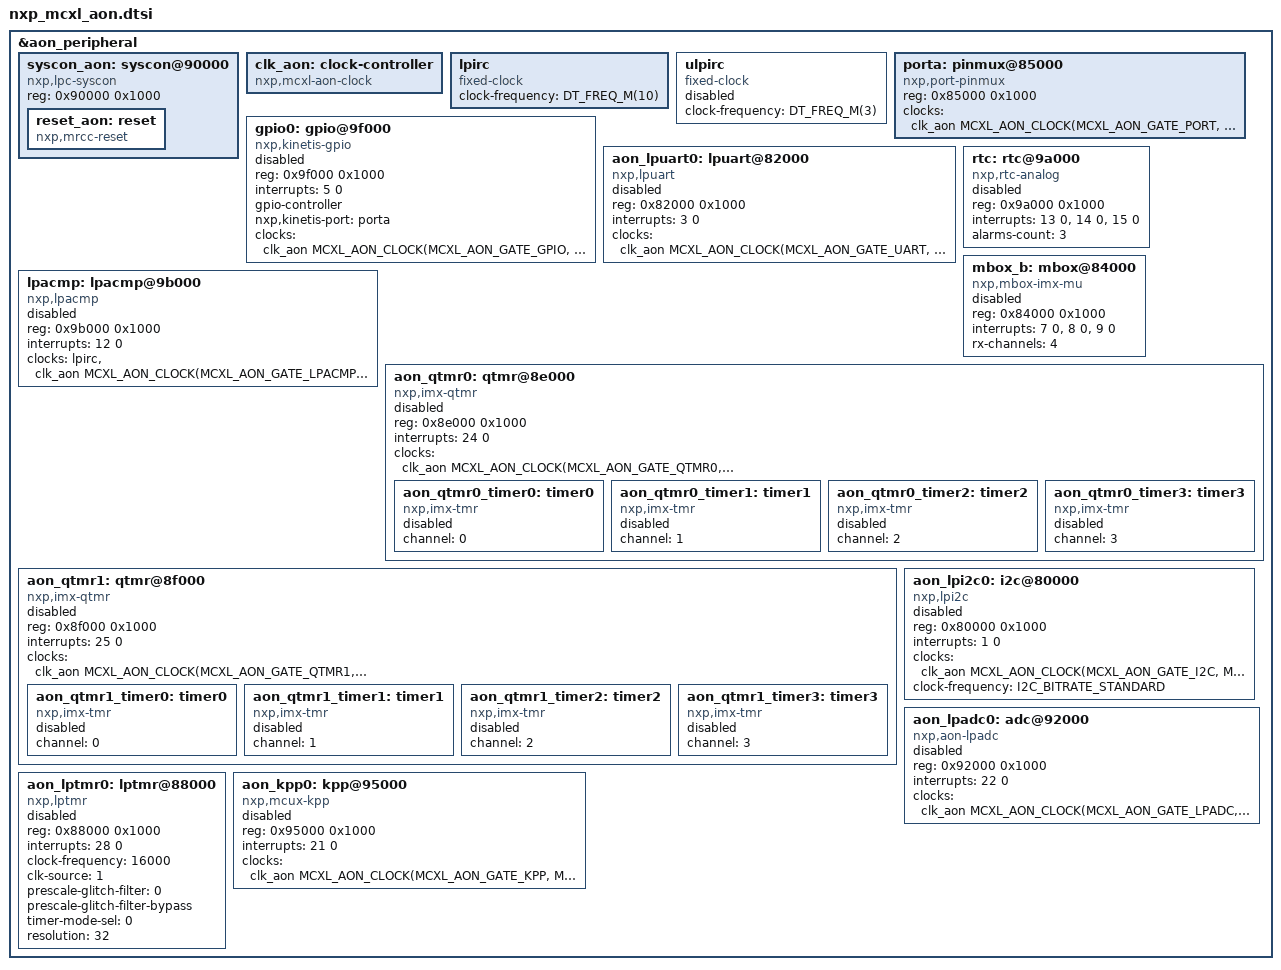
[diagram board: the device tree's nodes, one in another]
/*
 * Copyright 2026 NXP
 *
 * SPDX-License-Identifier: Apache-2.0
 */

#include <freq.h>
#include <zephyr/dt-bindings/clock/nxp_mcxl_aon_clock.h>
#include <zephyr/dt-bindings/i2c/i2c.h>
#include <zephyr/dt-bindings/reset/nxp_syscon_reset_common.h>

&aon_peripheral {
	#address-cells = <1>;
	#size-cells = <1>;

	syscon_aon: syscon@90000 {
		compatible = "nxp,lpc-syscon";
		reg = <0x90000 0x1000>;
		#clock-cells = <1>;

		reset_aon: reset {
			compatible = "nxp,mrcc-reset";
			#reset-cells = <1>;
		};
	};

	clk_aon: clock-controller {
		compatible = "nxp,mcxl-aon-clock";
		#clock-cells = <1>;
	};

	lpirc: lpirc {
		compatible = "fixed-clock";
		#clock-cells = <0>;
		clock-frequency = <DT_FREQ_M(10)>;
	};

	ulpirc: ulpirc {
		compatible = "fixed-clock";
		#clock-cells = <0>;
		clock-frequency = <DT_FREQ_M(3)>;
		status = "disabled";
	};

	porta: pinmux@85000 {
		compatible = "nxp,port-pinmux";
		reg = <0x85000 0x1000>;
		clocks = <&clk_aon MCXL_AON_CLOCK(MCXL_AON_GATE_PORT,
						  MCXL_AON_SEL_NONE, MCXL_AON_CLK_ROOT_SRC_NONE,
						  MCXL_AON_DIV_NONE, MCXL_CLOCK_DIV_BY_1,
						  MCXL_AON_CLK_FLAG_NONE)>;
	};

	gpio0: gpio@9f000 {
		compatible = "nxp,kinetis-gpio";
		status = "disabled";
		reg = <0x9f000 0x1000>;
		interrupts = <5 0>;
		gpio-controller;
		#gpio-cells = <2>;
		nxp,kinetis-port = <&porta>;
		clocks = <&clk_aon MCXL_AON_CLOCK(MCXL_AON_GATE_GPIO,
						  MCXL_AON_SEL_NONE, MCXL_AON_CLK_ROOT_SRC_NONE,
						  MCXL_AON_DIV_NONE, MCXL_CLOCK_DIV_BY_1,
						  MCXL_AON_CLK_FLAG_NONE)>;
	};

	aon_lpuart0: lpuart@82000 {
		compatible = "nxp,lpuart";
		status = "disabled";
		reg = <0x82000 0x1000>;
		interrupts = <3 0>;
		clocks = <&clk_aon MCXL_AON_CLOCK(MCXL_AON_GATE_UART,
						  MCXL_AON_SEL_NONE, MCXL_AON_CLK_ROOT_SRC_NONE,
						  MCXL_AON_DIV_NONE, MCXL_CLOCK_DIV_BY_1,
						  MCXL_AON_CLK_FLAG_NONE)>;
	};

	lpacmp: lpacmp@9b000 {
		compatible = "nxp,lpacmp";
		reg = <0x9b000 0x1000>;
		interrupts = <12 0>;
		clocks = <&lpirc>,
			 <&clk_aon MCXL_AON_CLOCK(MCXL_AON_GATE_LPACMP,
						  MCXL_AON_SEL_NONE, MCXL_AON_CLK_ROOT_SRC_NONE,
						  MCXL_AON_DIV_NONE, MCXL_CLOCK_DIV_BY_1,
						  MCXL_AON_CLK_FLAG_NONE)>;
		clock-names = "aon-clk", "gate";
		status = "disabled";
	};

	rtc: rtc@9a000 {
		compatible = "nxp,rtc-analog";
		reg = <0x9a000 0x1000>;
		interrupts = <13 0>, <14 0>, <15 0>;
		interrupt-names = "alarm0", "alarm1", "alarm2";
		alarms-count = <3>;
		status = "disabled";
	};

	mbox_b: mbox@84000 {
		compatible = "nxp,mbox-imx-mu";
		reg = <0x84000 0x1000>;
		interrupts = <7 0>, <8 0>, <9 0>;
		rx-channels = <4>;
		#mbox-cells = <1>;
		status = "disabled";
	};

	aon_qtmr0: qtmr@8e000 {
		compatible = "nxp,imx-qtmr";
		reg = <0x8e000 0x1000>;
		interrupts = <24 0>;
		clocks = <&clk_aon MCXL_AON_CLOCK(MCXL_AON_GATE_QTMR0,
						  MCXL_AON_SEL_NONE, MCXL_AON_CLK_ROOT_SRC_NONE,
						  MCXL_AON_DIV_NONE, MCXL_CLOCK_DIV_BY_1,
						  MCXL_AON_CLK_FLAG_NONE)>;
		status = "disabled";

		aon_qtmr0_timer0: timer0 {
			compatible = "nxp,imx-tmr";
			channel = <0>;
			status = "disabled";
		};

		aon_qtmr0_timer1: timer1 {
			compatible = "nxp,imx-tmr";
			channel = <1>;
			status = "disabled";
		};

		aon_qtmr0_timer2: timer2 {
			compatible = "nxp,imx-tmr";
			channel = <2>;
			status = "disabled";
		};

		aon_qtmr0_timer3: timer3 {
			compatible = "nxp,imx-tmr";
			channel = <3>;
			status = "disabled";
		};
	};

	aon_qtmr1: qtmr@8f000 {
		compatible = "nxp,imx-qtmr";
		reg = <0x8f000 0x1000>;
		interrupts = <25 0>;
		clocks = <&clk_aon MCXL_AON_CLOCK(MCXL_AON_GATE_QTMR1,
						  MCXL_AON_SEL_NONE, MCXL_AON_CLK_ROOT_SRC_NONE,
						  MCXL_AON_DIV_NONE, MCXL_CLOCK_DIV_BY_1,
						  MCXL_AON_CLK_FLAG_NONE)>;
		status = "disabled";

		aon_qtmr1_timer0: timer0 {
			compatible = "nxp,imx-tmr";
			channel = <0>;
			status = "disabled";
		};

		aon_qtmr1_timer1: timer1 {
			compatible = "nxp,imx-tmr";
			channel = <1>;
			status = "disabled";
		};

		aon_qtmr1_timer2: timer2 {
			compatible = "nxp,imx-tmr";
			channel = <2>;
			status = "disabled";
		};

		aon_qtmr1_timer3: timer3 {
			compatible = "nxp,imx-tmr";
			channel = <3>;
			status = "disabled";
		};
	};

	aon_lpi2c0: i2c@80000 {
		compatible = "nxp,lpi2c";
		status = "disabled";
		reg = <0x80000 0x1000>;
		interrupts = <1 0>;
		clocks = <&clk_aon MCXL_AON_CLOCK(MCXL_AON_GATE_I2C,
						  MCXL_AON_SEL_NONE, MCXL_AON_CLK_ROOT_SRC_NONE,
						  MCXL_AON_DIV_NONE, MCXL_CLOCK_DIV_BY_1,
						  MCXL_AON_CLK_FLAG_NONE)>;
		clock-frequency = <I2C_BITRATE_STANDARD>;
		#address-cells = <1>;
		#size-cells = <0>;
	};

	aon_lpadc0: adc@92000 {
		compatible = "nxp,aon-lpadc";
		reg = <0x92000 0x1000>;
		interrupts = <22 0>;
		clocks = <&clk_aon MCXL_AON_CLOCK(MCXL_AON_GATE_LPADC,
						  MCXL_AON_SEL_NONE, MCXL_AON_CLK_ROOT_SRC_NONE,
						  MCXL_AON_DIV_NONE, MCXL_CLOCK_DIV_BY_1,
						  MCXL_AON_CLK_FLAG_NONE)>;
		#io-channel-cells = <1>;
		status = "disabled";
	};

	aon_lptmr0: lptmr@88000 {
		compatible = "nxp,lptmr";
		reg = <0x88000 0x1000>;
		interrupts = <28 0>;
		clock-frequency = <16000>;
		clk-source = <1>;
		prescale-glitch-filter = <0>;
		prescale-glitch-filter-bypass;
		timer-mode-sel = <0>;
		resolution = <32>;
		status = "disabled";
	};
};

&aon_peripheral {
	aon_kpp0: kpp@95000 {
		compatible = "nxp,mcux-kpp";
		reg = <0x95000 0x1000>;
		interrupts = <21 0>;
		clocks = <&clk_aon MCXL_AON_CLOCK(MCXL_AON_GATE_KPP,
						  MCXL_AON_SEL_NONE, MCXL_AON_CLK_ROOT_SRC_NONE,
						  MCXL_AON_DIV_NONE, MCXL_CLOCK_DIV_BY_1,
						  MCXL_AON_CLK_FLAG_NONE)>;
		status = "disabled";
	};
};
